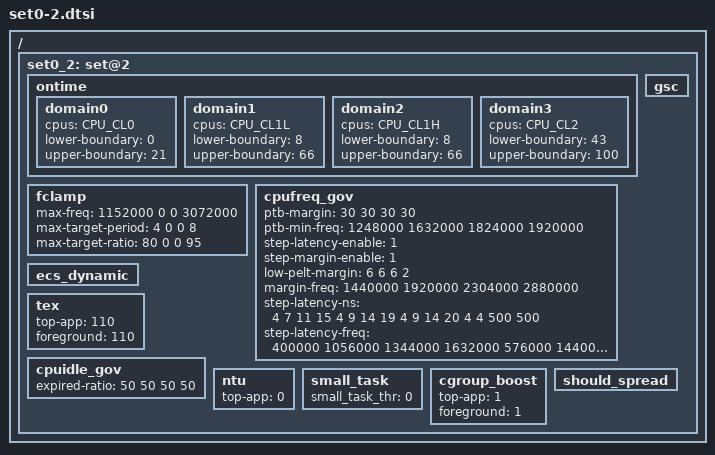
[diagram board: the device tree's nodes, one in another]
/ {
	/* normal mode - app boost */
	set0_2: set@2 {
		/* Ontime Migration */
		ontime {
			domain0 {
				cpus = CPU_CL0;
				lower-boundary = <0>;
				upper-boundary = <21>;
			};
			domain1 {
				cpus = CPU_CL1L;
				lower-boundary = <8>;
				upper-boundary = <66>;
			};
			domain2 {
				cpus = CPU_CL1H;
				lower-boundary = <8>;
				upper-boundary = <66>;
			};
			domain3 {
				cpus = CPU_CL2;
				lower-boundary = <43>;
				upper-boundary = <100>;
			};
		};

		fclamp {
			max-freq          = < 1152000       0      0 3072000>;
			max-target-period = <       4       0      0       8>;
			max-target-ratio  = <      80       0      0      95>;
		};

		cpufreq_gov {
				/* LIT MED-L MED-H BIG */
			ptb-margin = < 30 30 30 30 >;
			ptb-min-freq = < 1248000 1632000 1824000 1920000 >;

			step-latency-enable = < 1 >;
			step-margin-enable = < 1 >;

			low-pelt-margin = < 6 6 6 2 >;
			margin-freq = < 1440000 1920000 2304000 2880000 >;

				/* step1 step2 step3 step4 */
			step-latency-ns = < 4 7 11 15
					4 9 14 19
					4 9 14 20
					4 4 500 500 >;
			step-latency-freq = < 400000 1056000 1344000 1632000
					576000 1440000 1920000 2112000
					768000 1728000 2304000 2592000
					400000 400000 3072000 3072000 >;
		};


		ecs_dynamic { };

		tex {
			top-app = <110>;
			foreground = <110>;
		};

		gsc { };

		cpuidle_gov {
			expired-ratio = <50 50 50 50>;
		};

		ntu {
			top-app			= <0>;
		};

		small_task {
			small_task_thr = <0>;
		};

		cgroup_boost {
			top-app = <1>;
			foreground = <1>;
		};

		should_spread { };
	};
};
